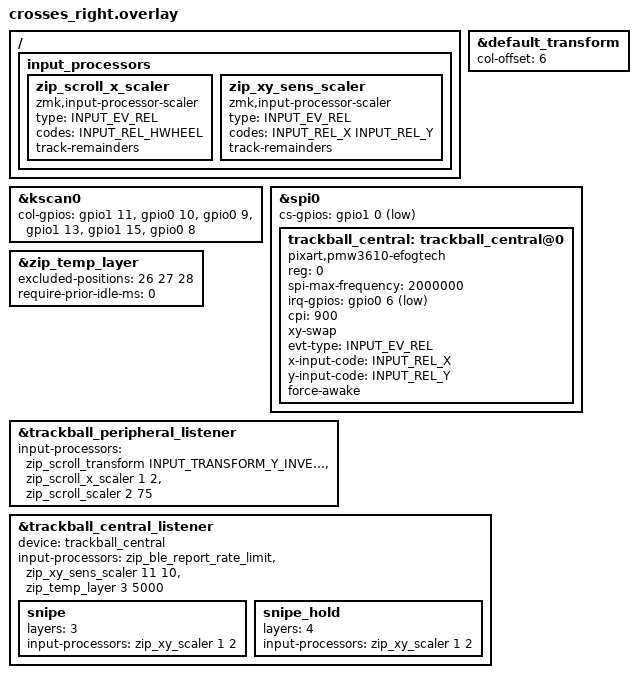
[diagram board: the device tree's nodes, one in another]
/*
 * Copyright (c) 2020 ZMK Contributors
 *
 * SPDX-License-Identifier: MIT
 */

#include "crosses.dtsi"
#include <zephyr/dt-bindings/input/input-event-codes.h>
#include <dt-bindings/zmk/input_transform.h>


&default_transform {
    col-offset = <6>;
};

&kscan0 {
    // 6 columns (official Crosses 54 right): outer col gpio0 8 added vs the 36 build
    col-gpios
        = <&gpio1 11 (GPIO_ACTIVE_HIGH | GPIO_PULL_DOWN)>
        , <&gpio0 10 (GPIO_ACTIVE_HIGH | GPIO_PULL_DOWN)>
        , <&gpio0 9 (GPIO_ACTIVE_HIGH | GPIO_PULL_DOWN)>
        , <&gpio1 13 (GPIO_ACTIVE_HIGH | GPIO_PULL_DOWN)>
        , <&gpio1 15 (GPIO_ACTIVE_HIGH | GPIO_PULL_DOWN)>
        , <&gpio0 8 (GPIO_ACTIVE_HIGH | GPIO_PULL_DOWN)>
        ;
};

// trackball bus (GCY03 verified pins for this AliExpress board: spi0, irq gpio0 6)
&spi0 {
    cs-gpios = <&gpio1 0 GPIO_ACTIVE_LOW>;

    trackball_central: trackball_central@0 {
        status = "okay";
        compatible = "pixart,pmw3610-efogtech";
        reg = <0>;
        spi-max-frequency = <2000000>;
        irq-gpios = <&gpio0 6 (GPIO_ACTIVE_LOW | GPIO_PULL_UP)>;
        cpi = <900>;
        xy-swap;
        evt-type = <INPUT_EV_REL>;
        x-input-code = <INPUT_REL_X>;
        y-input-code = <INPUT_REL_Y>;
        force-awake;
    };
};

/ {
    input_processors {
        zip_scroll_x_scaler: zip_scroll_x_scaler {
            compatible = "zmk,input-processor-scaler";
            #input-processor-cells = <2>;
            type = <INPUT_EV_REL>;
            codes = <INPUT_REL_HWHEEL>;
            track-remainders;
        };

        // 커서 감도 보정용 (세로/가로 동시). snipe 와 별도 노드 → remainder 충돌 방지
        zip_xy_sens_scaler: zip_xy_sens_scaler {
            compatible = "zmk,input-processor-scaler";
            #input-processor-cells = <2>;
            type = <INPUT_EV_REL>;
            codes = <INPUT_REL_X INPUT_REL_Y>;
            track-remainders;
        };
    };
};

// auto-mouse layer (layer 3 = Mouse) auto-exit guard.
// excluded positions = mouse-click keys on the Mouse layer (RCLK/MCLK/LCLK)
&zip_temp_layer {
    excluded-positions = <26 27 28>;
    require-prior-idle-ms = <0>; //진입 즉시 (타이핑 직후에도 트랙볼 움직이면 바로)
};

// LEFT trackball = scroll only (inverted direction, 2/3 speed)
&trackball_peripheral_listener {
    status = "okay";
    input-processors = <
        &zip_scroll_transform INPUT_TRANSFORM_Y_INVERT //세로 스크롤 방향 반전 (휠 굴리는 방향)
        &zip_scroll_x_scaler 1 2 //가로 스크롤 = 세로의 약 절반. 이전 1/30(가로 30배 죽임) → 15배 회복
        &zip_scroll_scaler 2 75 //세로/가로 공통 스크롤 속도(가로도 동일 적용 → 세로와 동급)
    >;
};

// RIGHT trackball = cursor + auto-mouse layer + precision(hold)
&trackball_central_listener {
    status = "okay";
    device = <&trackball_central>;
    input-processors = <
        &zip_ble_report_rate_limit
        &zip_xy_sens_scaler 11 10 //커서 감도 +10% (base → snipe 레이어에도 누적 적용)
        &zip_temp_layer 3 5000 //오토마우스 레이어 (레이어 3 = Mouse), 나가기 5초
    >;

    //정밀 (오토마우스 레이어 연동)
    snipe {
        layers = <3>;
        input-processors = <
            &zip_xy_scaler 1 2
        >;
    };

    //정밀모드(버튼 홀드용) - 레이어 4 (Snipe_Hold) 활성 시 커서 1/2 속도
    snipe_hold {
        layers = <4>;
        input-processors = <
            &zip_xy_scaler 1 2 //더 느리게 하려면 1 3
        >;
    };
};
